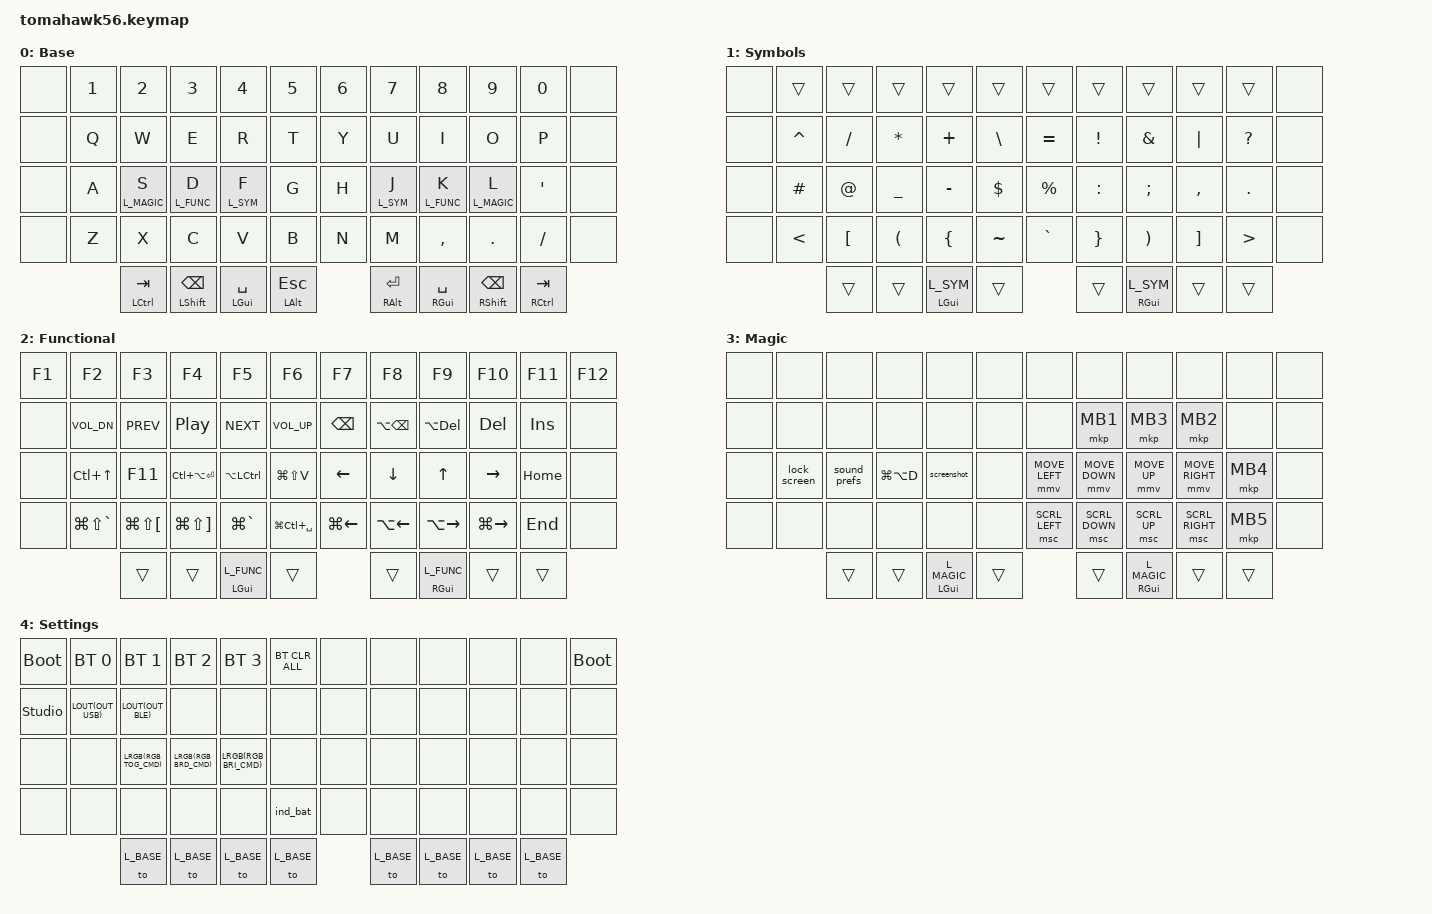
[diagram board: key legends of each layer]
/*
 * Tomahawk56 keymap
 * SPDX-License-Identifier: MIT
 */

#include <behaviors.dtsi>
#include <behaviors/rgbled_widget.dtsi>
#include <dt-bindings/zmk/bt.h>
#include <dt-bindings/zmk/keys.h>
#include <dt-bindings/zmk/outputs.h>
#include <dt-bindings/zmk/rgb.h>
#define ZMK_POINTING_DEFAULT_MOVE_VAL 750
#include <dt-bindings/zmk/pointing.h>

#define L_BASE  0
#define L_SYM   1
#define L_FUNC  2
#define L_MAGIC 3
#define L_SET   4

/* Quicker ramp-up for Magic-layer cursor movement; scrolling stays stock. */
&mmv {
    time-to-max-speed-ms = <250>;
};

/* Route controls through lrgb_sync so each press immediately refreshes its indicator. */
#define LRGB(cmd) &lrgb_sync (0x100 + (cmd)) 0
#define LOUT(cmd) &lrgb_sync (0x200 + (cmd)) 0

/*
 * Key positions, as used by the combos below:
 * four rows of twelve, then eight thumbs.
 *
 *    0  1  2  3  4  5     6  7  8  9 10 11
 *   12 13 14 15 16 17    18 19 20 21 22 23
 *   24 25 26 27 28 29    30 31 32 33 34 35
 *   36 37 38 39 40 41    42 43 44 45 46 47
 *         48 49 50 51    52 53 54 55
 */

nice_view_spi: &spi0 { cs-gpios = <&pro_micro 4 GPIO_ACTIVE_HIGH>; };

&led_strip {
    chain-length = <28>;
};

/ {
    behaviors {
        /* The node name must fit ZMK's eight-byte split-behavior field. */
        lrgb_sync: lrgb {
            compatible = "zmk,behavior-layer-rgb-sync";
            #binding-cells = <2>;
        };

        /*
         * Tap the letter, hold for the layer. Overlapping letters must remain
         * typing in either release order: another key never forces a hold.
         * Eligible holds resolve after 165 ms. Targets pressed earlier are
         * buffered and replayed on the layer, so same-hand held chords work
         * without waiting before pressing their target.
         *
         * The idle guard still forces taps during a typing burst, and quick
         * taps protect doubled letters ("ss", "ll"). A letter held past the
         * term can still become a layer outside those guards.
         * Keep the hold as plain &mo: &lrgb_sync is global-locality and would
         * put a blocking split BLE send on the key-press path.
         */
        layer_tap_left: layer_tap_left {
            compatible = "zmk,behavior-hold-tap";
            #binding-cells = <2>;
            flavor = "tap-preferred";
            tapping-term-ms = <165>;
            quick-tap-ms = <200>;
            require-prior-idle-ms = <100>;
            bindings = <&mo>, <&kp>;
        };

        layer_tap_right: layer_tap_right {
            compatible = "zmk,behavior-hold-tap";
            #binding-cells = <2>;
            flavor = "tap-preferred";
            tapping-term-ms = <165>;
            quick-tap-ms = <200>;
            require-prior-idle-ms = <100>;
            bindings = <&mo>, <&kp>;
        };

        /* Chords resolve Cmd on key-down, even immediately after a toggle tap. */
        cmd_tog: cmd_tog {
            compatible = "zmk,behavior-hold-tap";
            #binding-cells = <2>;
            flavor = "hold-preferred";
            tapping-term-ms = <225>;
            quick-tap-ms = <0>;
            bindings = <&kp>, <&tog>;
        };

        /*
         * Tab/Ctrl and Escape/Enter/Option resolve chords on the next key-down.
         * Recent typing and repeated taps must not veto the modifier.
         */
        safe_mt: safe_mod_tap {
            compatible = "zmk,behavior-hold-tap";
            #binding-cells = <2>;
            flavor = "hold-preferred";
            tapping-term-ms = <175>;
            quick-tap-ms = <0>;
            require-prior-idle-ms = <0>;
            bindings = <&kp>, <&kp>;
        };

        /*
         * Shift has its own policy so capitalization can be tuned separately.
         * Tap Backspace, then hold or chord to Shift immediately. There is no
         * tap-then-hold Backspace repeat; use taps or Functional-layer Backspace.
         */
        shift_mt: shift_mod_tap {
            compatible = "zmk,behavior-hold-tap";
            #binding-cells = <2>;
            flavor = "hold-preferred";
            tapping-term-ms = <175>;
            quick-tap-ms = <0>;
            require-prior-idle-ms = <0>;
            bindings = <&kp>, <&kp>;
        };

        /* The idle guard keeps Space a tap during continuous typing. */
        safe_space_mt: safe_space_mod_tap {
            compatible = "zmk,behavior-hold-tap";
            #binding-cells = <2>;
            flavor = "balanced";
            tapping-term-ms = <225>;
            quick-tap-ms = <200>;
            require-prior-idle-ms = <80>;
            bindings = <&kp>, <&kp>;
        };
    };

    macros {
        ZMK_MACRO(lock_screen,
            bindings
                = <&macro_press &kp LCTRL &kp LGUI>
                , <&macro_tap &kp Q>
                , <&macro_release &kp LGUI &kp LCTRL>
                ;
        )

        ZMK_MACRO(sound_prefs,
            bindings
                = <&macro_press &kp LALT>
                , <&macro_tap &kp C_VOL_UP>
                , <&macro_release &kp LALT>
                ;
        )

        ZMK_MACRO(screenshot,
            bindings
                = <&macro_press &kp LGUI &kp LSHFT>
                , <&macro_tap &kp N4>
                , <&macro_release &kp LSHFT &kp LGUI>
                ;
        )
    };

    combos {
        compatible = "zmk,combos";

        /*
         * Both positions are &none on every layer, so Settings needs no
         * prior-idle guard. Including L_SET makes the same squeeze exit.
         */
        settings_left {
            timeout-ms = <100>;
            key-positions = <24 36>; /* left of A + left of Z */
            bindings = <&tog L_SET>;
            layers = <L_BASE L_SET>;
        };

        settings_right {
            timeout-ms = <100>;
            key-positions = <35 47>; /* right of ' + right of / */
            bindings = <&tog L_SET>;
            layers = <L_BASE L_SET>;
        };
    };

    keymap {
        compatible = "zmk,keymap";

        base_layer {
            display-name = "Base";
// ----------------------------------------------------------------------------------------------------------------
// | NONE |  1  |  2  |   3   |   4   |  5  |        |  6  |  7  |   8   |   9   |  0  | NONE |
// | NONE |  Q  |  W  |   E   |   R   |  T  |        |  Y  |  U  |   I   |   O   |  P  | NONE |
// | SET  |  A  | S/M3| D/M2  | F/M1  |  G  |        |  H  | J/M1| K/M2  | L/M3  |  '  | SET  |
// | SET  |  Z  |  X  |   C   |   V   |  B  |        |  N  |  M  |   ,   |   .   |  /  | SET  |
//              |TAB/C|BSPC/S |SPACE/G|ESC/A  |      |ENTER/A|SPACE/G|BSPC/S|TAB/C |
//
// SET marks the outer pairs that enter Settings, squeezed two at a time; they
// are dead on their own. Tap then re-press Space within quick-tap-ms to repeat
// it. Backspace repeats via separate taps or the Functional-layer Backspace.
            bindings = <
&none        &kp N1  &kp N2                    &kp N3                   &kp N4                  &kp N5       &kp N6  &kp N7                    &kp N8                   &kp N9                  &kp N0                  &none
&none        &kp Q   &kp W                     &kp E                    &kp R                   &kp T        &kp Y   &kp U                     &kp I                    &kp O                   &kp P                   &none
&none        &kp A   &layer_tap_left L_MAGIC S &layer_tap_left L_FUNC D &layer_tap_left L_SYM F &kp G        &kp H   &layer_tap_right L_SYM J &layer_tap_right L_FUNC K &layer_tap_right L_MAGIC L &kp SQT                 &none
&none        &kp Z   &kp X                     &kp C                    &kp V                   &kp B        &kp N   &kp M                     &kp COMMA                &kp DOT                 &kp FSLH                &none
                    &safe_mt LCTRL TAB  &shift_mt LSHFT BSPC  &safe_space_mt LGUI SPACE  &safe_mt LALT ESC          &safe_mt RALT ENTER  &safe_space_mt RGUI SPACE  &shift_mt RSHFT BSPC  &safe_mt RCTRL TAB
            >;
        };

        symbols_layer {
            display-name = "Symbols";
// ----------------------------------------------------------------------------------------------------------------
// | NONE |TRNS |TRNS | TRNS | TRNS | TRNS |        | TRNS |TRNS |TRNS |TRNS |TRNS |NONE |
// | NONE |  ^  |  /  |  *   |  +   |  \  |        |  =   |  !  |  &  |  |  |  ?  |NONE |
// | NONE |  #  |  @  |  _   |  -   |  $   |        |  %   |  :  |  ;  |  ,  |  .  |NONE |
// | NONE |  <  |  [  |  (   |  {   |  ~   |        |  `   |  }  |  )  |  ]  |  >  |NONE |
//              |TRNS |TRNS  |CMD/TOG|TRNS |       |TRNS |CMD/TOG|TRNS |TRNS |
            bindings = <
&none  &trans     &trans     &trans     &trans      &trans      &trans     &trans      &trans    &trans     &trans  &none
&none  &kp CARET  &kp FSLH   &kp STAR   &kp PLUS    &kp BSLH    &kp EQUAL  &kp EXCL    &kp AMPS  &kp PIPE   &kp QMARK &none
&none  &kp HASH   &kp AT     &kp UNDER  &kp MINUS   &kp DOLLAR  &kp PRCNT  &kp COLON   &kp SEMI  &kp COMMA  &kp DOT   &none
&none  &kp LT     &kp LBKT   &kp LPAR   &kp LBRC    &kp TILDE   &kp GRAVE  &kp RBRC    &kp RPAR  &kp RBKT   &kp GT    &none
                   &trans  &trans  &cmd_tog LGUI L_SYM  &trans    &trans  &cmd_tog RGUI L_SYM  &trans  &trans
            >;
        };

        functional_layer {
            display-name = "Functional";
// ----------------------------------------------------------------------------------------------------------------
// | F1   | F2       | F3       | F4       | F5       | F6       | F7      | F8       | F9       | F10      | F11      | F12  |
// | NONE | VOL-     | PREV     | PLAY     | NEXT     | VOL+     | BSPC    | OPT+BSPC | OPT+DEL  | DEL      | INSERT   | NONE |
// | NONE | CTRL+UP  | F11      | C+A+ENT  | OPT+CTRL | G+S+V    | LEFT    | DOWN     | UP       | RIGHT    | HOME     | NONE |
// | NONE | G+S+`    | G+S+[    | G+S+]    | G+`      | G+C+SPC  | G+LEFT  | A+LEFT   | A+RIGHT  | G+RIGHT  | END      | NONE |
//                   |TRNS |TRNS |CMD/TOG|TRNS |      |TRNS |CMD/TOG|TRNS |TRNS |
            bindings = <
&kp F1  &kp F2             &kp F3             &kp F4             &kp F5          &kp F6            &kp F7        &kp F8       &kp F9        &kp F10       &kp F11        &kp F12
&none   &kp C_VOL_DN       &kp C_PREV         &kp C_PP           &kp C_NEXT      &kp C_VOL_UP      &kp BSPC      &kp LA(BSPC) &kp LA(DEL)   &kp DEL       &kp INSERT     &none
&none   &kp LC(UP)         &kp F11            &kp LC(LA(ENTER))  &kp LA(LCTRL)  &kp LG(LS(V))     &kp LEFT      &kp DOWN     &kp UP        &kp RIGHT     &kp HOME       &none
&none   &kp LG(LS(GRAVE))  &kp LG(LS(LBKT))   &kp LG(LS(RBKT))  &kp LG(GRAVE)  &kp LG(LC(SPACE)) &kp LG(LEFT)  &kp LA(LEFT) &kp LA(RIGHT) &kp LG(RIGHT) &kp END        &none
                         &trans  &trans  &cmd_tog LGUI L_FUNC  &trans    &trans  &cmd_tog RGUI L_FUNC  &trans  &trans
            >;
        };

        magic_layer {
            display-name = "Magic";
// ----------------------------------------------------------------------------------------------------------------
// | NONE | NONE | NONE  | NONE | NONE | NONE |       | NONE | NONE | NONE | NONE | NONE | NONE |
// | NONE | NONE | NONE  | NONE | NONE | NONE |       | NONE | MB1  | MB3  | MB2  | NONE | NONE |
// | NONE | LOCK | SOUND | DOCK | SHOT | NONE |       | M<   | Mv   | M^   | M>   | MB4  | NONE |
// | NONE | NONE | NONE  | NONE | NONE | NONE |       | S<   | Sv   | S^   | S>   | MB5  | NONE |
//                    |TRNS |TRNS |CMD/TOG|TRNS |     |TRNS |CMD/TOG|TRNS |TRNS |
            bindings = <
&none  &none                 &none                  &none               &none        &none       &none              &none              &none             &none               &none       &none
&none  &none                 &none                  &none               &none        &none       &none              &mkp MB1           &mkp MB3          &mkp MB2            &none       &none
&none  &lock_screen          &sound_prefs           &kp LG(LA(D))       &screenshot  &none       &mmv MOVE_LEFT     &mmv MOVE_DOWN     &mmv MOVE_UP      &mmv MOVE_RIGHT     &mkp MB4   &none
&none  &none                 &none                  &none               &none        &none       &msc SCRL_LEFT     &msc SCRL_DOWN     &msc SCRL_UP      &msc SCRL_RIGHT     &mkp MB5   &none
                            &trans  &trans  &cmd_tog LGUI L_MAGIC  &trans    &trans  &cmd_tog RGUI L_MAGIC  &trans  &trans
            >;
        };

        /*
         * Settings is latched for repeated controls. Unused positions are
         * &none so the layer cannot type accidental host input.
         *
         * &bootloader is event-source local, so each corner targets its half.
         * &ind_bat may block on a global split send and therefore stays off Base.
         */
        settings_layer {
            display-name = "Settings";
// ----------------------------------------------------------------------------------------------------------------
// | BOOT | BT1   | BT2  | BT3  | BT4  | CLR* |     | NONE | NONE | NONE | NONE | NONE  | BOOT |
// |UNLCK | USB   | BLE  | NONE | NONE | NONE |     | NONE | NONE | NONE | NONE | NONE  | NONE |
// | SET  | NONE  | RGB  | BRI- | BRI+ | NONE |     | NONE | NONE | NONE | NONE | NONE  | SET  |
// | SET  | NONE  | NONE | NONE | NONE | BATT |     | NONE | NONE | NONE | NONE | NONE  | SET  |
//               |EXIT |EXIT |EXIT |EXIT |            |EXIT |EXIT |EXIT |EXIT |
//
// * CLR is &bt BT_CLR_ALL: forgets all four pairings at once, not undoable.
//
// Profile keys must remain on this row: rgbled-widget's position-to-pixel
// formula agrees with the renderer's physical LED map only here. RGB controls
// stay a row away to prevent a brightness slip from switching profiles.
            bindings = <
&bootloader     &bt BT_SEL 0   &bt BT_SEL 1       &bt BT_SEL 2       &bt BT_SEL 3       &bt BT_CLR_ALL  &none  &none  &none  &none  &none  &bootloader
&studio_unlock  LOUT(OUT_USB)  LOUT(OUT_BLE)      &none              &none              &none           &none  &none  &none  &none  &none  &none
&none           &none          LRGB(RGB_TOG_CMD)  LRGB(RGB_BRD_CMD)  LRGB(RGB_BRI_CMD)  &none           &none  &none  &none  &none  &none  &none
&none           &none          &none              &none              &none              &ind_bat        &none  &none  &none  &none  &none  &none
                       &to L_BASE  &to L_BASE  &to L_BASE  &to L_BASE        &to L_BASE  &to L_BASE  &to L_BASE  &to L_BASE
            >;
        };
    };
};
